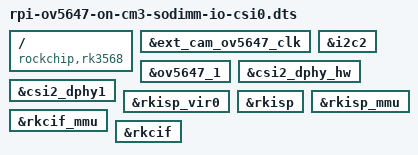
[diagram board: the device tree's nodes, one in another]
/dts-v1/;
/plugin/;

/ {
	compatible = "rockchip,rk3568";

	fragment@0 {
		target = <&ext_cam_ov5647_clk>;

		__overlay__ {
			status = "okay";
		};
	};

	fragment@1 {
		target = <&i2c2>;

		__overlay__ {
			status = "okay";
		};
	};

	fragment@2 {
		target = <&ov5647_1>;

		__overlay__ {
			status = "okay";
		};
	};

	fragment@3 {
		target = <&csi2_dphy_hw>;

		__overlay__ {
			status = "okay";
		};
	};

	fragment@4 {
		target = <&csi2_dphy1>;

		__overlay__ {
			status = "okay";
		};
	};

	fragment@5 {
		target = <&rkisp_vir0>;

		__overlay__ {
			status = "okay";
		};
	};

	fragment@6 {
		target = <&rkisp>;

		__overlay__ {
			status = "okay";
		};
	};

	fragment@7 {
		target = <&rkisp_mmu>;

		__overlay__ {
			status = "okay";
		};
	};

	fragment@8 {
		target = <&rkcif_mmu>;

		__overlay__ {
			status = "okay";
		};
	};

	fragment@9 {
		target = <&rkcif>;

		__overlay__ {
			status = "okay";
		};
	};
};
